AUTOSAR XML (schema 00046)
package /ComponentTypes
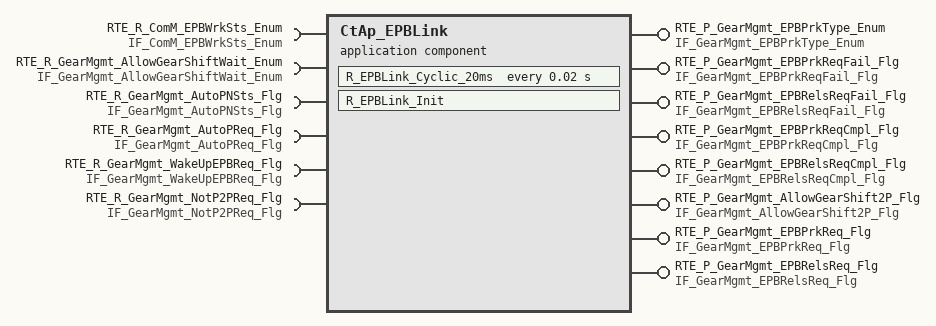
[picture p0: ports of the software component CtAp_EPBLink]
  application sw component type CtAp_EPBLink
    6 x require port:
      RTE_R_ComM_EPBWrkSts_Enum: nonqueued-receiver-com-spec{data-element=tec_ComM_EPBWrkSts_Enum, filter=data-filter-type=ALWAYS, init-value=0}, required-interface=IF_ComM_EPBWrkSts_Enum
      RTE_R_GearMgmt_AllowGearShiftWait_Enum: nonqueued-receiver-com-spec{data-element=tec_GearMgmt_AllowGearShiftWait_Enum, filter=data-filter-type=ALWAYS, init-value=0}, required-interface=IF_GearMgmt_AllowGearShiftWait_Enum
      RTE_R_GearMgmt_AutoPNSts_Flg: nonqueued-receiver-com-spec{data-element=tec_GearMgmt_AutoPNSts_Flg, filter=data-filter-type=ALWAYS, init-value=0}, required-interface=IF_GearMgmt_AutoPNSts_Flg
      RTE_R_GearMgmt_AutoPReq_Flg: nonqueued-receiver-com-spec{data-element=tec_GearMgmt_AutoPReq_Flg, filter=data-filter-type=ALWAYS, init-value=0}, required-interface=IF_GearMgmt_AutoPReq_Flg
      RTE_R_GearMgmt_WakeUpEPBReq_Flg: nonqueued-receiver-com-spec{data-element=tec_GearMgmt_WakeUpEPBReq_Flg, filter=data-filter-type=ALWAYS, init-value=0}, required-interface=IF_GearMgmt_WakeUpEPBReq_Flg
      RTE_R_GearMgmt_NotP2PReq_Flg: nonqueued-receiver-com-spec{data-element=tec_GearMgmt_NotP2PReq_Flg, filter=data-filter-type=ALWAYS, init-value=0}, required-interface=IF_GearMgmt_NotP2PReq_Flg
    8 x provide port:
      RTE_P_GearMgmt_EPBPrkType_Enum: nonqueued-sender-com-spec{data-element=tec_GearMgmt_EPBPrkType_Enum, init-value=0}, provided-interface=IF_GearMgmt_EPBPrkType_Enum
      RTE_P_GearMgmt_EPBPrkReqFail_Flg: nonqueued-sender-com-spec{data-element=tec_GearMgmt_EPBPrkReqFail_Flg, init-value=0}, provided-interface=IF_GearMgmt_EPBPrkReqFail_Flg
      RTE_P_GearMgmt_EPBRelsReqFail_Flg: nonqueued-sender-com-spec{data-element=tec_GearMgmt_EPBRelsReqFail_Flg, init-value=0}, provided-interface=IF_GearMgmt_EPBRelsReqFail_Flg
      RTE_P_GearMgmt_EPBPrkReqCmpl_Flg: nonqueued-sender-com-spec{data-element=tec_GearMgmt_EPBPrkReqCmpl_Flg, init-value=0}, provided-interface=IF_GearMgmt_EPBPrkReqCmpl_Flg
      RTE_P_GearMgmt_EPBRelsReqCmpl_Flg: nonqueued-sender-com-spec{data-element=tec_GearMgmt_EPBRelsReqCmpl_Flg, init-value=0}, provided-interface=IF_GearMgmt_EPBRelsReqCmpl_Flg
      RTE_P_GearMgmt_AllowGearShift2P_Flg: nonqueued-sender-com-spec{data-element=tec_GearMgmt_AllowGearShift2P_Flg, init-value=0}, provided-interface=IF_GearMgmt_AllowGearShift2P_Flg
      RTE_P_GearMgmt_EPBPrkReq_Flg: nonqueued-sender-com-spec{data-element=tec_GearMgmt_EPBPrkReq_Flg, init-value=0}, provided-interface=IF_GearMgmt_EPBPrkReq_Flg
      RTE_P_GearMgmt_EPBRelsReq_Flg: nonqueued-sender-com-spec{data-element=tec_GearMgmt_EPBRelsReq_Flg, init-value=0}, provided-interface=IF_GearMgmt_EPBRelsReq_Flg
    behavior CtAp_EPBLink_InternalBehavior
      init event CtAp_EPBLink_InitEvent: start-on-event=R_EPBLink_Init
      timing event TMT_R_EPBLink_Cyclic_20ms: start-on-event=R_EPBLink_Cyclic_20ms, period=0.02
      runnable R_EPBLink_Init
      runnable R_EPBLink_Cyclic_20ms
        data-receive-point-by-arguments:
          6 x access:
            REC_RTE_R_ComM_EPBWrkSts_Enum_tec_ComM_EPBWrkSts_Enum: accessed-variable=RTE_R_ComM_EPBWrkSts_Enum.tec_ComM_EPBWrkSts_Enum
            REC_RTE_R_GearMgmt_AllowGearShiftWait_Enum_tec_GearMgmt_AllowGearShiftWait_Enum: accessed-variable=RTE_R_GearMgmt_AllowGearShiftWait_Enum.tec_GearMgmt_AllowGearShiftWait_Enum
            REC_RTE_R_GearMgmt_AutoPNSts_Flg_tec_GearMgmt_AutoPNSts_Flg: accessed-variable=RTE_R_GearMgmt_AutoPNSts_Flg.tec_GearMgmt_AutoPNSts_Flg
            REC_RTE_R_GearMgmt_AutoPReq_Flg_tec_GearMgmt_AutoPReq_Flg: accessed-variable=RTE_R_GearMgmt_AutoPReq_Flg.tec_GearMgmt_AutoPReq_Flg
            REC_RTE_R_GearMgmt_NotP2PReq_Flg_tec_GearMgmt_NotP2PReq_Flg: accessed-variable=RTE_R_GearMgmt_NotP2PReq_Flg.tec_GearMgmt_NotP2PReq_Flg
            REC_RTE_R_GearMgmt_WakeUpEPBReq_Flg_tec_GearMgmt_WakeUpEPBReq_Flg: accessed-variable=RTE_R_GearMgmt_WakeUpEPBReq_Flg.tec_GearMgmt_WakeUpEPBReq_Flg
        data-send-points:
          8 x access:
            SEND_RTE_P_GearMgmt_AllowGearShift2P_Flg_tec_GearMgmt_AllowGearShift2P_Flg: accessed-variable=RTE_P_GearMgmt_AllowGearShift2P_Flg.tec_GearMgmt_AllowGearShift2P_Flg
            SEND_RTE_P_GearMgmt_EPBPrkReqCmpl_Flg_tec_GearMgmt_EPBPrkReqCmpl_Flg: accessed-variable=RTE_P_GearMgmt_EPBPrkReqCmpl_Flg.tec_GearMgmt_EPBPrkReqCmpl_Flg
            SEND_RTE_P_GearMgmt_EPBPrkReqFail_Flg_tec_GearMgmt_EPBPrkReqFail_Flg: accessed-variable=RTE_P_GearMgmt_EPBPrkReqFail_Flg.tec_GearMgmt_EPBPrkReqFail_Flg
            SEND_RTE_P_GearMgmt_EPBPrkReq_Flg_tec_GearMgmt_EPBPrkReq_Flg: accessed-variable=RTE_P_GearMgmt_EPBPrkReq_Flg.tec_GearMgmt_EPBPrkReq_Flg
            SEND_RTE_P_GearMgmt_EPBPrkType_Enum_tec_GearMgmt_EPBPrkType_Enum: accessed-variable=RTE_P_GearMgmt_EPBPrkType_Enum.tec_GearMgmt_EPBPrkType_Enum
            SEND_RTE_P_GearMgmt_EPBRelsReqCmpl_Flg_tec_GearMgmt_EPBRelsReqCmpl_Flg: accessed-variable=RTE_P_GearMgmt_EPBRelsReqCmpl_Flg.tec_GearMgmt_EPBRelsReqCmpl_Flg
            SEND_RTE_P_GearMgmt_EPBRelsReqFail_Flg_tec_GearMgmt_EPBRelsReqFail_Flg: accessed-variable=RTE_P_GearMgmt_EPBRelsReqFail_Flg.tec_GearMgmt_EPBRelsReqFail_Flg
            SEND_RTE_P_GearMgmt_EPBRelsReq_Flg_tec_GearMgmt_EPBRelsReq_Flg: accessed-variable=RTE_P_GearMgmt_EPBRelsReq_Flg.tec_GearMgmt_EPBRelsReq_Flg
  swc implementation CtAp_EPBLink_Implementation: behavior=CtAp_EPBLink_InternalBehavior
    code-descriptors:
      code Default: artifact-descriptors=autosar-engineering-object=category=SWOBJ
